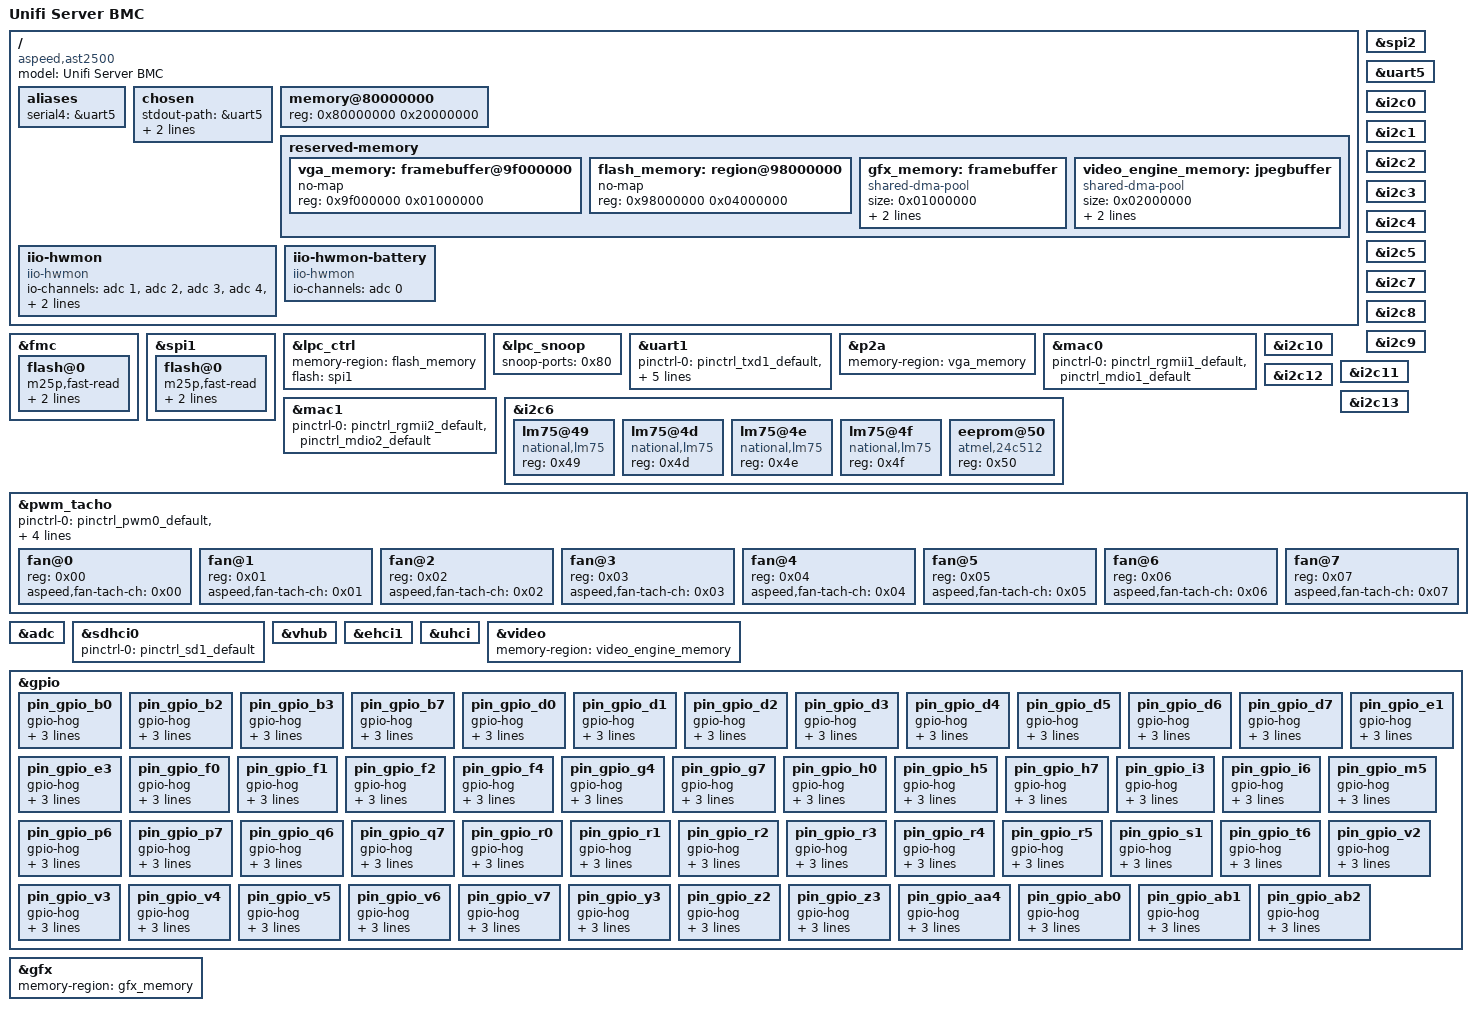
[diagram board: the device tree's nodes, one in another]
// SPDX-License-Identifier: GPL-2.0+
/dts-v1/;

#include "aspeed-g5.dtsi"
#include <dt-bindings/gpio/aspeed-gpio.h>

/ {
	model = "Unifi Server BMC";
	compatible = "aspeed,ast2500";

	aliases {
		serial4 = &uart5;
	};

	chosen {
		stdout-path = &uart5;
		bootargs = "console=tty0 console=ttyS4,115200 earlyprintk";
	};

	memory@80000000 {
		reg = <0x80000000 0x20000000>;
	};

	reserved-memory {
		#address-cells = <1>;
		#size-cells = <1>;
		ranges;

		vga_memory: framebuffer@9f000000 {
			no-map;
			reg = <0x9f000000 0x01000000>; /* 16M */
		};

		flash_memory: region@98000000 {
			no-map;
			reg = <0x98000000 0x04000000>; /* 64M */
		};

		gfx_memory: framebuffer {
			size = <0x01000000>;
			alignment = <0x01000000>;
			compatible = "shared-dma-pool";
			reusable;
		};

		video_engine_memory: jpegbuffer {
			size = <0x02000000>;	/* 32M */
			alignment = <0x01000000>;
			compatible = "shared-dma-pool";
			reusable;
		};
	};

	iio-hwmon {
		compatible = "iio-hwmon";
		io-channels = <&adc 1>, <&adc 2>, <&adc 3>, <&adc 4>,
			<&adc 5>, <&adc 6>, <&adc 7>, <&adc 8>,
			<&adc 9>, <&adc 10>, <&adc 11>, <&adc 12>,
			<&adc 13>, <&adc 14>, <&adc 15>;
	};

	iio-hwmon-battery {
		compatible = "iio-hwmon";
		io-channels = <&adc 0>;
	};
};

&fmc {
	status = "okay";
	flash@0 {
		status = "okay";
		m25p,fast-read;
		label = "bmc";
		spi-max-frequency = <50000000>;
#include "openbmc-flash-layout.dtsi"
	};
};

&spi1 {
	status = "okay";
	flash@0 {
		status = "okay";
		m25p,fast-read;
		label = "pnor";
		spi-max-frequency = <100000000>;
	};
};

&spi2 {
	status = "okay";
};

&lpc_ctrl {
	status = "okay";
	memory-region = <&flash_memory>;
	flash = <&spi1>;
};

&lpc_snoop {
	status = "okay";
	snoop-ports = <0x80>;
};

&uart1 {
	status = "okay";
	pinctrl-names = "default";
	pinctrl-0 = <&pinctrl_txd1_default
			&pinctrl_rxd1_default
			&pinctrl_nrts1_default
			&pinctrl_ndtr1_default
			&pinctrl_ndsr1_default
			&pinctrl_ncts1_default
			&pinctrl_ndcd1_default
			&pinctrl_nri1_default>;
};

&uart5 {
	status = "okay";
};

&p2a {
	status = "okay";
	memory-region = <&vga_memory>;
};

&mac0 {
	status = "okay";

	pinctrl-names = "default";
	pinctrl-0 = <&pinctrl_rgmii1_default &pinctrl_mdio1_default>;
};

&mac1 {
	status = "okay";

	pinctrl-names = "default";
	pinctrl-0 = <&pinctrl_rgmii2_default &pinctrl_mdio2_default>;
};

&i2c0 {
	status = "okay";
};

&i2c1 {
	status = "okay";
};

&i2c2 {
	status = "okay";
};

&i2c3 {
	status = "okay";
};

&i2c4 {
	status = "okay";
};

&i2c5 {
	status = "okay";
};

&i2c6 {
	status = "okay";

	lm75@49 {
		compatible = "national,lm75";
		reg = <0x49>;
	};

	lm75@4d {
		compatible = "national,lm75";
		reg = <0x4d>;
	};

	lm75@4e {
		compatible = "national,lm75";
		reg = <0x4e>;
	};

	lm75@4f {
		compatible = "national,lm75";
		reg = <0x4f>;
	};

	eeprom@50 {
		compatible = "atmel,24c512";
		reg = <0x50>;
	};
};

&i2c7 {
	status = "okay";
};

&i2c8 {
	status = "okay";
};

&i2c9 {
	status = "okay";
};

&i2c10 {
	status = "okay";
};

&i2c11 {
	status = "okay";
};

&i2c12 {
	status = "okay";
};

&i2c13 {
	status = "okay";
};


&pwm_tacho {
	status = "okay";

	pinctrl-names = "default";
	pinctrl-0 = <&pinctrl_pwm0_default
		&pinctrl_pwm1_default
		&pinctrl_pwm2_default
		&pinctrl_pwm3_default
		&pinctrl_pwm4_default
		&pinctrl_pwm5_default
		&pinctrl_pwm6_default
		&pinctrl_pwm7_default>;

	fan@0 {
		reg = <0x00>;
		aspeed,fan-tach-ch = /bits/ 8 <0x00>;
	};

	fan@1 {
		reg = <0x01>;
		aspeed,fan-tach-ch = /bits/ 8 <0x01>;
	};

	fan@2 {
		reg = <0x02>;
		aspeed,fan-tach-ch = /bits/ 8 <0x02>;
	};

	fan@3 {
		reg = <0x03>;
		aspeed,fan-tach-ch = /bits/ 8 <0x03>;
	};

	fan@4 {
		reg = <0x04>;
		aspeed,fan-tach-ch = /bits/ 8 <0x04>;
	};

	fan@5 {
		reg = <0x05>;
		aspeed,fan-tach-ch = /bits/ 8 <0x05>;
	};

	fan@6 {
		reg = <0x06>;
		aspeed,fan-tach-ch = /bits/ 8 <0x06>;
	};

	fan@7 {
		reg = <0x07>;
		aspeed,fan-tach-ch = /bits/ 8 <0x07>;
	};
};

&adc {
	status = "okay";
};

&sdhci0 {
	status = "okay";

	pinctrl-names = "default";
	pinctrl-0 = <&pinctrl_sd1_default>;
};

/*
 * Enable port A as device (via the virtual hub) and port B as
 * host by default on the eval board. This can be easily changed
 * by replacing the override below with &ehci0 { ... } to enable
 * host on both ports.
 */
&vhub {
	status = "okay";
};

&ehci1 {
	status = "okay";
};

&uhci {
	status = "okay";
};

&video {
	status = "okay";
	memory-region = <&video_engine_memory>;
};

&gpio {
	pin_gpio_b0 {
		gpio-hog;
		gpios = <ASPEED_GPIO(B, 0) GPIO_ACTIVE_HIGH>;
		output-high;
		line-name = "FP_ID_LED_BMC_N";
	};

	pin_gpio_b2 {
		gpio-hog;
		gpios = <ASPEED_GPIO(B, 2) GPIO_ACTIVE_HIGH>;
		output-high;
		line-name = "FM_ME_RCVR_N";
	};

	pin_gpio_b3 {
		gpio-hog;
		gpios = <ASPEED_GPIO(B, 3) GPIO_ACTIVE_HIGH>;
		output-high;
		line-name = "JTAG_PLD_SW1_SEL_R";
	};

	pin_gpio_b7 {
		gpio-hog;
		gpios = <ASPEED_GPIO(B, 7) GPIO_ACTIVE_LOW>;
		output-high;
		line-name = "JTAG_PLD_SW1_OE_R";
	};

	pin_gpio_d0 {
		gpio-hog;
		gpios = <ASPEED_GPIO(D, 0) GPIO_ACTIVE_HIGH>;
		input;
		line-name = "FM_CPU0_ABC_MEMHOT_LVT3_N";
	};

	pin_gpio_d1 {
		gpio-hog;
		gpios = <ASPEED_GPIO(D, 1) GPIO_ACTIVE_HIGH>;
		input;
		line-name = "FM_CPU0_DEF_MEMHOT_LVT3_N";
	};

	pin_gpio_d2 {
		gpio-hog;
		gpios = <ASPEED_GPIO(D, 2) GPIO_ACTIVE_HIGH>;
		input;
		line-name = "FM_CPU1_GHJ_MEMHOT_LVT3_N";
	};

	pin_gpio_d3 {
		gpio-hog;
		gpios = <ASPEED_GPIO(D, 3) GPIO_ACTIVE_HIGH>;
		input;
		line-name = "FM_CPU1_KLM_MEMHOT_LVT3_N";
	};

	pin_gpio_d4 {
		gpio-hog;
		gpios = <ASPEED_GPIO(D, 4) GPIO_ACTIVE_HIGH>;
		input;
		line-name = "FM_FORCE_BMC_UPDATE_N";
	};

	pin_gpio_d5 {
		gpio-hog;
		gpios = <ASPEED_GPIO(D, 5) GPIO_ACTIVE_LOW>;
		output-high;
		line-name = "BMC_PHY_RESET_R_N";
	};

	pin_gpio_d6 {
		gpio-hog;
		gpios = <ASPEED_GPIO(D, 6) GPIO_ACTIVE_LOW>;
		output-high;
		line-name = "TP_GPIOD6";
	};

	pin_gpio_d7 {
		gpio-hog;
		gpios = <ASPEED_GPIO(D, 7) GPIO_ACTIVE_LOW>;
		output-high;
		line-name = "RST_RTCRST_BMCOUT_N";
	};

	pin_gpio_e1 {
		gpio-hog;
		gpios = <ASPEED_GPIO(E, 1) GPIO_ACTIVE_HIGH>;
		output-high;
		line-name = "RST_BMC_RSTBTN_OUT_N";
	};

	pin_gpio_e3 {
		gpio-hog;
		gpios = <ASPEED_GPIO(E, 3) GPIO_ACTIVE_HIGH>;
		output-high;
		line-name = "FW_BMC_PWR_BTN_N";
	};

	pin_gpio_f0 {
		gpio-hog;
		gpios = <ASPEED_GPIO(F, 0) GPIO_ACTIVE_HIGH>;
		output-low;
		line-name = "IRQ_BMC_PCH_NMI";
	};

	pin_gpio_f1 {
		gpio-hog;
		gpios = <ASPEED_GPIO(F, 1) GPIO_ACTIVE_HIGH>;
		output-high;
		line-name = "FM_CPU1_DISABLE_COD_N";
	};

	pin_gpio_f2 {
		gpio-hog;
		gpios = <ASPEED_GPIO(F, 2) GPIO_ACTIVE_HIGH>;
		output-high;
		line-name = "FM_BMC_FLASH_WP_N";
	};

	pin_gpio_f4 {
		gpio-hog;
		gpios = <ASPEED_GPIO(F, 4) GPIO_ACTIVE_HIGH>;
		output-low;
		line-name = "FM_SKT0_FAULT_LED";
	};

	pin_gpio_g4 {
		gpio-hog;
		gpios = <ASPEED_GPIO(G, 4) GPIO_ACTIVE_HIGH>;
		output-low;
		line-name = "FM_SPI_SEL";
	};

	pin_gpio_g7 {
		gpio-hog;
		gpios = <ASPEED_GPIO(G, 7) GPIO_ACTIVE_HIGH>;
		output-high;
		line-name = "VGA_CONN_R_SEL";
	};

	pin_gpio_h0 {
		gpio-hog;
		gpios = <ASPEED_GPIO(H, 0) GPIO_ACTIVE_HIGH>;
		output-high;
		line-name = "XDP_SYSPWROK";
	};

	pin_gpio_h5 {
		gpio-hog;
		gpios = <ASPEED_GPIO(H, 5) GPIO_ACTIVE_HIGH>;
		output-low;
		line-name = "FM_SKT1_FAULT_LED";
	};

	pin_gpio_h7 {
		gpio-hog;
		gpios = <ASPEED_GPIO(H, 7) GPIO_ACTIVE_HIGH>;
		output-low;
		line-name = "TP_GPIOH7";
	};

	pin_gpio_i3 {
		gpio-hog;
		gpios = <ASPEED_GPIO(I, 3) GPIO_ACTIVE_HIGH>;
		output-low;
		line-name = "VBAT_TEST_EN";
	};

	pin_gpio_i6 {
		gpio-hog;
		gpios = <ASPEED_GPIO(I, 6) GPIO_ACTIVE_HIGH>;
		output-high;
		line-name = "BMC_XDP_TCK_MUX_SEL";
	};

	pin_gpio_m5 {
		gpio-hog;
		gpios = <ASPEED_GPIO(M, 5) GPIO_ACTIVE_HIGH>;
		output-high;
		line-name = "BMC_REMOTEJTAG_EN_R";
	};

	pin_gpio_p6 {
		gpio-hog;
		gpios = <ASPEED_GPIO(P, 6) GPIO_ACTIVE_HIGH>;
		input;
		line-name = "RST_PLTRST_BMC_N";
	};

	pin_gpio_p7 {
		gpio-hog;
		gpios = <ASPEED_GPIO(P, 7) GPIO_ACTIVE_HIGH>;
		output-low;
		line-name = "AUD_HDA_SDO";
	};

	pin_gpio_q6 {
		gpio-hog;
		gpios = <ASPEED_GPIO(Q, 6) GPIO_ACTIVE_HIGH>;
		output-high;
		line-name = "SMB_SMLINK4_MUX_SEL_R";
	};

	pin_gpio_q7 {
		gpio-hog;
		gpios = <ASPEED_GPIO(Q, 7) GPIO_ACTIVE_HIGH>;
		output-high;
		line-name = "IRQ_LVC3_WAKE_R_N";
	};

	pin_gpio_r0 {
		gpio-hog;
		gpios = <ASPEED_GPIO(R, 0) GPIO_ACTIVE_HIGH>;
		input;
		line-name = "FM_CPU_THERMTRIP_LVT3_N";
	};

	pin_gpio_r1 {
		gpio-hog;
		gpios = <ASPEED_GPIO(R, 1) GPIO_ACTIVE_HIGH>;
		input;
		line-name = "IBMC_FLA_CS2_N";
	};

	pin_gpio_r2 {
		gpio-hog;
		gpios = <ASPEED_GPIO(R, 2) GPIO_ACTIVE_LOW>;
		input;
		line-name = "TP_BMC_SPI2_CS0_N";
	};

	pin_gpio_r3 {
		gpio-hog;
		gpios = <ASPEED_GPIO(R, 3) GPIO_ACTIVE_LOW>;
		input;
		line-name = "TP_BMC_SPI2_CLK";
	};

	pin_gpio_r4 {
		gpio-hog;
		gpios = <ASPEED_GPIO(R, 4) GPIO_ACTIVE_LOW>;
		input;
		line-name = "TP_BMC_SPI2_MOSI";
	};

	pin_gpio_r5 {
		gpio-hog;
		gpios = <ASPEED_GPIO(R, 5) GPIO_ACTIVE_LOW>;
		input;
		line-name = "TP_BMC_SPI2_MISO";
	};

	pin_gpio_s1 {
		gpio-hog;
		gpios = <ASPEED_GPIO(S, 1) GPIO_ACTIVE_HIGH>;
		output-high;
		line-name = "IRQ_BMC_PCH_SMI_LPC_N";
	};

	pin_gpio_t6 {
		gpio-hog;
		gpios = <ASPEED_GPIO(T, 6) GPIO_ACTIVE_HIGH>;
		input;
		line-name = "RISER4_SLOT_PRES_R_N";
	};

	pin_gpio_v2 {
		gpio-hog;
		gpios = <ASPEED_GPIO(V, 2) GPIO_ACTIVE_LOW>;
		input;
		line-name = "PD_GPIOV2";
	};

	pin_gpio_v3 {
		gpio-hog;
		gpios = <ASPEED_GPIO(V, 3) GPIO_ACTIVE_LOW>;
		input;
		line-name = "PD_GPIOV3";
	};

	pin_gpio_v4 {
		gpio-hog;
		gpios = <ASPEED_GPIO(V, 4) GPIO_ACTIVE_LOW>;
		input;
		line-name = "PD_GPIOV4";
	};

	pin_gpio_v5 {
		gpio-hog;
		gpios = <ASPEED_GPIO(V, 5) GPIO_ACTIVE_LOW>;
		input;
		line-name = "PD_GPIOV5";
	};

	pin_gpio_v6 {
		gpio-hog;
		gpios = <ASPEED_GPIO(V, 6) GPIO_ACTIVE_LOW>;
		input;
		line-name = "PD_GPIOV6";
	};

	pin_gpio_v7 {
		gpio-hog;
		gpios = <ASPEED_GPIO(V, 7) GPIO_ACTIVE_LOW>;
		input;
		line-name = "PD_GPIOV7";
	};

	pin_gpio_y3 {
		gpio-hog;
		gpios = <ASPEED_GPIO(Y, 3) GPIO_ACTIVE_HIGH>;
		output-high;
		line-name = "FM_BMC_ONCTL_R_N";
	};

	pin_gpio_z2 {
		gpio-hog;
		gpios = <ASPEED_GPIO(Z, 2) GPIO_ACTIVE_LOW>;
		output-low;
		line-name = "FM_BMC_PWRBTN_OUT_N";
	};

	pin_gpio_z3 {
		gpio-hog;
		gpios = <ASPEED_GPIO(Z, 3) GPIO_ACTIVE_HIGH>;
		output-high;
		line-name = "FM_BMC_PCH_SCI_LPC_N";
	};

	pin_gpio_aa4 {
		gpio-hog;
		gpios = <ASPEED_GPIO(AA, 4) GPIO_ACTIVE_HIGH>;
		output-low;
		line-name = "SPEAKER_BMC";
	};

	pin_gpio_ab0 {
		gpio-hog;
		gpios = <ASPEED_GPIO(AB, 0) GPIO_ACTIVE_HIGH>;
		output-high;
		line-name = "BMC_XDP_PREQ_N";
	};

	pin_gpio_ab1 {
		gpio-hog;
		gpios = <ASPEED_GPIO(AB, 1) GPIO_ACTIVE_HIGH>;
		output-high;
		line-name = "BMC_XDP_PWR_DEBUG_N";
	};

	pin_gpio_ab2 {
		gpio-hog;
		gpios = <ASPEED_GPIO(AB, 2) GPIO_ACTIVE_HIGH>;
		output-high;
		line-name = "BMC_PRDY_CLR_N";
	};
};


&gfx {
     status = "okay";
     memory-region = <&gfx_memory>;
};
